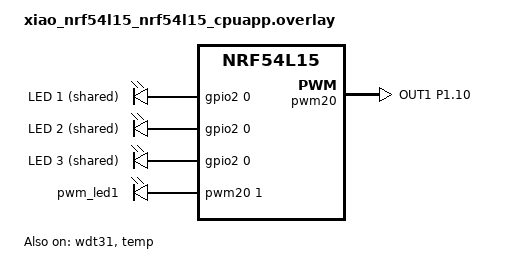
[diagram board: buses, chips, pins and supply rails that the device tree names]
/* XIAO nRF54L15 overlay for the Matter light bulb, derived from Nordic's
 * nrf54l15dk overlay. Same SoC; no external flash on the XIAO, so no
 * nordic,pm-ext-flash and no MCUboot secondary slot. PWM on P1.10 = XIAO D4. */
/ {
	aliases {
		pwm-led1 = &pwm_led1;
		watchdog0 = &wdt31;
	};
	/* The XIAO defines a single led0. Nordic's dk_buttons_and_leds builds its
	 * LED table from the children of /leds, and Matter's AppTask drives
	 * DK_LED1..DK_LED4, so with one child it indexes out of range and faults
	 * at boot. Add three more children on the same physical LED (gpio2 0) —
	 * harmless, and avoids claiming header pins D0-D10. */
	leds {
		led1: led_1 { gpios = <&gpio2 0 GPIO_ACTIVE_HIGH>; label = "LED 1 (shared)"; };
		led2: led_2 { gpios = <&gpio2 0 GPIO_ACTIVE_HIGH>; label = "LED 2 (shared)"; };
		led3: led_3 { gpios = <&gpio2 0 GPIO_ACTIVE_HIGH>; label = "LED 3 (shared)"; };
	};
	pwmleds {
		compatible = "pwm-leds";
		pwm_led1: pwm_led_1 {
			pwms = <&pwm20 1 PWM_MSEC(20) PWM_POLARITY_NORMAL>;
		};
	};
};
/* restore full RRAM and SRAM (parts are reserved for the FLPR core by default) */
&cpuapp_rram { reg = <0x0 DT_SIZE_K(1524)>; };
&cpuapp_sram { reg = <0x20000000 DT_SIZE_K(256)>; ranges = <0x0 0x20000000 0x40000>; };
&pwm20 {
	status = "okay";
	pinctrl-0 = <&pwm_default>;
	pinctrl-1 = <&pwm_sleep>;
	pinctrl-names = "default", "sleep";
};
&pinctrl {
	pwm_default: pwm_default { group1 { psels = <NRF_PSEL(PWM_OUT1, 1, 10)>; }; };
	pwm_sleep:   pwm_sleep   { group1 { psels = <NRF_PSEL(PWM_OUT1, 1, 10)>; low-power-enable; }; };
};
&wdt31 { status = "okay"; };

/* die temperature sensor for 802.15.4 radio calibration */
&temp { status = "okay"; };
